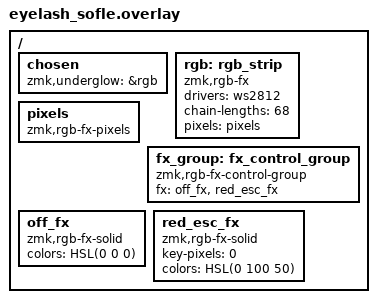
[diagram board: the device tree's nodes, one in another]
#include <dt-bindings/zmk/rgb_fx.h>

/ {
    chosen {
        zmk,underglow = &rgb;
    };

    rgb: rgb_strip {
        compatible = "zmk,rgb-fx";
        drivers = <&ws2812>;
        chain-lengths = <68>;
        pixels = <&pixels>;
    };

    pixels: pixels {
        compatible = "zmk,rgb-fx-pixels";
    };

    fx_group: fx_control_group {
        compatible = "zmk,rgb-fx-control-group";
        fx = <&off_fx &red_esc_fx>;
    };

    off_fx: off_fx {
        compatible = "zmk,rgb-fx-solid";
        colors = <HSL(0 0 0)>;
    };

    red_esc_fx: red_esc_fx {
        compatible = "zmk,rgb-fx-solid";
        key-pixels = <0>;
        colors = <HSL(0 100 50)>;
    };
};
